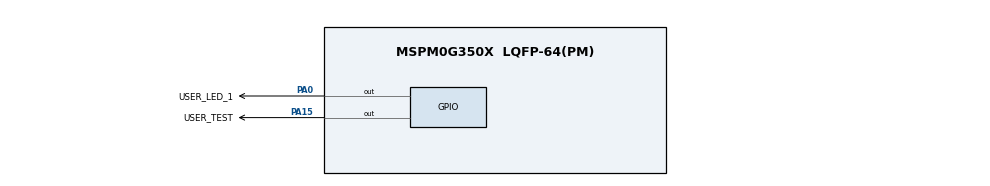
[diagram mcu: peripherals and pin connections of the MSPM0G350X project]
// @cliArgs --device "MSPM0G350X" --package "LQFP-64(PM)" --part "Default"
// @cliArgs --board /ti/boards/LP_MSPM0G3507 --rtos nortos

/**
 * Import the modules used in this configuration.
 */
const DMA    = scripting.addModule("/ti/driverlib/DMA");
const GPIO   = scripting.addModule("/ti/driverlib/GPIO", {}, false);
const GPIO1  = GPIO.addInstance();
const SYSCTL = scripting.addModule("/ti/driverlib/SYSCTL");

/**
 * Write custom configuration values to the imported modules.
 */
DMA.associatedChannels.create(1);
DMA.associatedChannels[0].$name              = "DMA_CH0";
DMA.associatedChannels[0].transferMode       = "SINGLE_BLOCK";
DMA.associatedChannels[0].enableInterrupt    = true;
DMA.associatedChannels[0].addressMode        = "b2b";
DMA.associatedChannels[0].srcLength          = "WORD";
DMA.associatedChannels[0].peripheral.$assign = "DMA_CH0";

GPIO1.$name                          = "GPIO_LEDS";
GPIO1.associatedPins.create(2);
GPIO1.associatedPins[0].$name        = "USER_LED_1";
GPIO1.associatedPins[0].initialValue = "SET";
GPIO1.associatedPins[0].pin.$assign  = "PA0";
GPIO1.associatedPins[1].$name        = "USER_TEST";
GPIO1.associatedPins[1].initialValue = "SET";
GPIO1.associatedPins[1].pin.$assign  = "PA15";

const Board = scripting.addModule("/ti/driverlib/Board", {}, false);

SYSCTL.forceDefaultClkConfig = true;
SYSCTL.clockTreeEn  = true;
